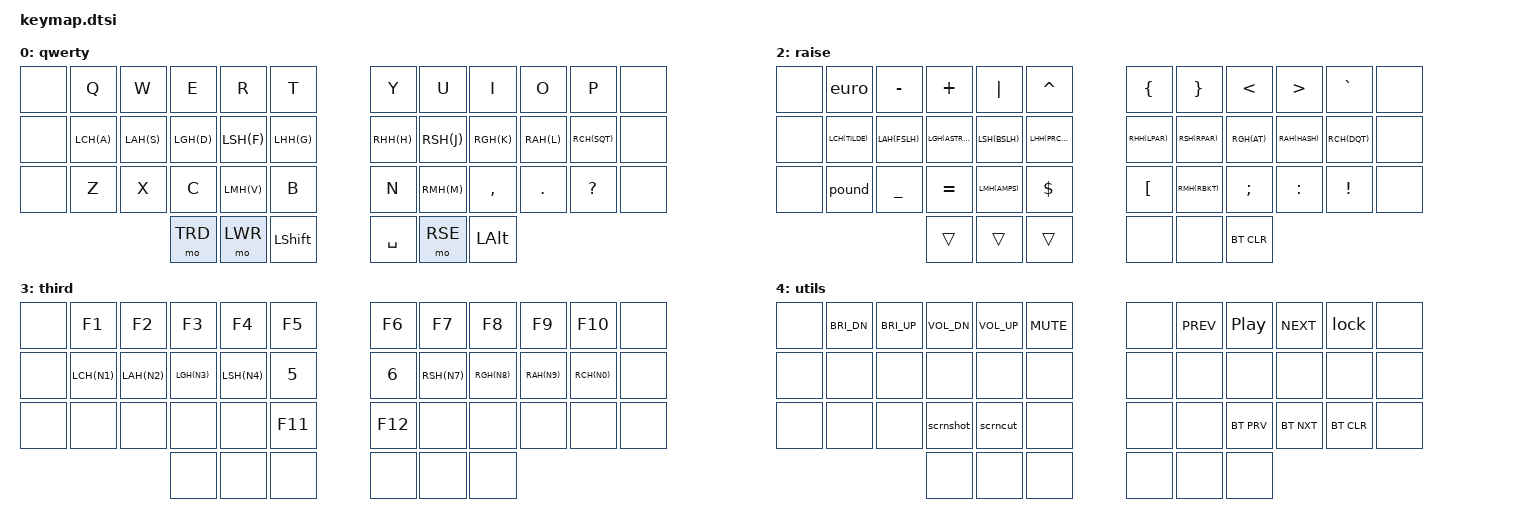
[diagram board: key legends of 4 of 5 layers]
/ {
    keymap {
        compatible = "zmk,keymap";
        qwerty {
            bindings = <
            /*╭───────╭───────────┬───────────┬───────────┬───────────┬───────────╮                           ╭───────────┬───────────┬───────────┬───────────┬───────────╮───────╮*/
            /*│       │     Q     │     W     │     E     │     R     │     T     │                           │     Y     │     U     │     I     │     O     │     P     │       │*/
                &none   &kp Q       &kp W       &kp E       &kp R       &kp T     /*                         */ &kp Y       &kp U       &kp I       &kp O       &kp P       &none
            /*├───────├───────────┼───────────┼───────────┼───────────┼───────────┤                           ├───────────┼───────────┼───────────┼───────────┼───────────┤───────┤*/
            /*│       │     A     │     S     │     D     │     F     │     G     │                           │     H     │     J     │     K     │     L     │     '     │       │*/
                &none   LCH(A)      LAH(S)      LGH(D)      LSH(F)      LHH(G)    /*                         */ RHH(H)      RSH(J)      RGH(K)      RAH(L)      RCH(SQT)    &none
            /*├───────├───────────┼───────────┼───────────┼───────────┼───────────┤                           ├───────────┼───────────┼───────────┼───────────┼───────────┤───────┤*/
            /*│       │     Z     │     X     │     C     │     V     │     B     │                           │     N     │     M     │     ,     │     .     │     ?     │       │*/
                &none   &kp Z       &kp X       &kp C       LMH(V)      &kp B     /*──────────╮   ╭──────────*/ &kp N       RMH(M)      &kp COMMA   &kp DOT     &kp QMARK   &none
            /*╰───────╰───────────┴───────────┴───────────┼───────────┼───────────┤           │   │           ├───────────┼───────────┼───────────┴───────────┴───────────╯───────╯*/
            /*                                            │           │           │   shift   │   │   space   │           │    alt    │                                            */
                                                            &mo TRD     &mo LWR     &kp LSHIFT/* */ &kp SPACE   &mo RSE     &kp LALT
            /*                                            ╰───────────┴───────────┤           │   │           ├───────────┴───────────╯                                            */
            /*                                                                    ╰───────────╯   ╰───────────╯                                                                    */
            >;
        };
        lower {
            bindings = <
            /*╭───────╭───────────┬───────────┬───────────┬───────────┬───────────╮                           ╭───────────┬───────────┬───────────┬───────────┬───────────╮───────╮*/
            /*│       │           │           │           │           │           │                           │           │           │           │           │           │       │*/
                &none   &kp BRI_DN  &kp BRI_UP  &kp VOL_DN  &kp VOL_UP  &kp MUTE  /*                         */ &none       &kp C_PREV  &kp C_PP    &kp C_NEXT  &lock       &none
            /*├───────├───────────┼───────────┼───────────┼───────────┼───────────┤                           ├───────────┼───────────┼───────────┼───────────┼───────────┤───────┤*/
            /*│       │    ctrl   │    alt    │    cmd    │   shift   │ CAPS word │                           │     <     │     v     │     ^     │     >     │           │       │*/
                &none   &kp LCTRL   &kp LALT    &kp LGUI    &kp LSHIFT  &caps_word/*                         */ &kp LEFT    &kp DOWN    &kp UP      &kp RIGHT   &none       &none
            /*├───────├───────────┼───────────┼───────────┼───────────┼───────────┤                           ├───────────┼───────────┼───────────┼───────────┼───────────┤───────┤*/
            /*│       │           │           │ screenshot│ screencut │           │                           │ backspace │   enter   │    tab    │    esc    │   delete  │       │*/
                &none   &none       &none       &scrnshot   &scrncut    RP        /*──────────╮   ╭──────────*/ &kp BSPC    &kp RET     &kp TAB     &kp ESC     &kp DEL     &none
            /*╰───────╰───────────┴───────────┴───────────┼───────────┼───────────┤           │   │           ├───────────┼───────────┼───────────┴───────────┴───────────╯───────╯*/
            /*                                            │           │[activator]│           │   │           │           │           │                                            */
                                                            &bt BT_CLR  &none       &none     /* */ &trans      &trans      &trans 
            /*                                            ╰───────────┴───────────┤           │   │           ├───────────┴───────────╯                                            */
            /*                                                                    ╰───────────╯   ╰───────────╯                                                                    */
            >;
        };
        raise {
            bindings = <
            /*╭───────╭───────────┬───────────┬───────────┬───────────┬───────────╮                           ╭───────────┬───────────┬───────────┬───────────┬───────────╮───────╮*/
            /*│       │     €     │     -     │     +     │     |     │     ^     │                           │     {     │     }     │     <     │     >     │     `     │       │*/
                &none   &euro       &kp MINUS   &kp PLUS    &kp PIPE    &kp CARET /*                         */ &kp LBRC    &kp RBRC    &kp LT      &kp GT      &kp GRAVE   &none
            /*├───────├───────────┼───────────┼───────────┼───────────┼───────────┤                           ├───────────┼───────────┼───────────┼───────────┼───────────┤───────┤*/
            /*│       │     ~     │     /     │     *     │     \     │     %     │                           │     (     │     )     │     @     │     #     │     "     │       │*/
                &none   LCH(TILDE)  LAH(FSLH)   LGH(ASTRK)  LSH(BSLH)   LHH(PRCNT)/*                         */ RHH(LPAR)   RSH(RPAR)   RGH(AT)     RAH(HASH)   RCH(DQT)    &none
            /*├───────├───────────┼───────────┼───────────┼───────────┼───────────┤                           ├───────────┼───────────┼───────────┼───────────┼───────────┤───────┤*/
            /*│       │     £     │     _     │     =     │     &     │     $     │                           │     [     │     ]     │     ;     │     :     │     !     │       │*/
                &none   &pound      &kp UNDER   &kp EQUAL   LMH(AMPS)   &kp DLLR  /*──────────╮   ╭──────────*/ &kp LBKT    RMH(RBKT)   &kp SEMI    &kp COLON   &kp EXCL    &none
            /*╰───────╰───────────┴───────────┴───────────┼───────────┼───────────┤           │   │           ├───────────┼───────────┼───────────┴───────────┴───────────╯───────╯*/
            /*                                            │           │           │           │   │           │[activator]│           │                                            */
                                                            &trans      &trans      &trans    /* */ &none       &none       &bt BT_CLR
            /*                                            ╰───────────┴───────────┤           │   │           ├───────────┴───────────╯                                            */
            /*                                                                    ╰───────────╯   ╰───────────╯                                                                    */
            >;
        };
        third {
            bindings = <
            /*╭───────╭───────────┬───────────┬───────────┬───────────┬───────────╮                           ╭───────────┬───────────┬───────────┬───────────┬───────────╮───────╮*/
            /*│       │    F1     │    F2     │    F3     │    F4     │    F5     │                           │    F6     │    F7     │    F8     │    F9     │    F10    │       │*/
                &none   &kp F1      &kp F2      &kp F3      &kp F4      &kp F5    /*                         */ &kp F6      &kp F7      &kp F8      &kp F9      &kp F10     &none
            /*├───────├───────────┼───────────┼───────────┼───────────┼───────────┤                           ├───────────┼───────────┼───────────┼───────────┼───────────┤───────┤*/
            /*│       │     1     │     2     │     3     │     4     │     5     │                           │     6     │     7     │     8     │     9     │     10    │       │*/
                &none   LCH(N1)     LAH(N2)     LGH(N3)     LSH(N4)     &kp N5    /*                         */ &kp N6      RSH(N7)     RGH(N8)     RAH(N9)     RCH(N0)     &none
            /*├───────├───────────┼───────────┼───────────┼───────────┼───────────┤                           ├───────────┼───────────┼───────────┼───────────┼───────────┤───────┤*/
            /*│       │           │           │           │           │    F11    │                           │    F12    │           │           │           │           │       │*/
                &none   &none       &none       &none       &none       &kp F11   /*──────────╮   ╭──────────*/ &kp F12     &none       &none       &none       &none       &none
            /*╰───────╰───────────┴───────────┴───────────┼───────────┼───────────┤           │   │           ├───────────┼───────────┼───────────┴───────────┴───────────╯───────╯*/
            /*                                            │[activator]│           │           │   │           │           │           │                                            */
                                                            &none       &none       &none     /* */ &none       &none       &none
            /*                                            ╰───────────┴───────────┤           │   │           ├───────────┴───────────╯                                            */
            /*                                                                    ╰───────────╯   ╰───────────╯                                                                    */
            >;
        };
        utils {
            bindings = <
            /*╭───────╭───────────┬───────────┬───────────┬───────────┬───────────╮                           ╭───────────┬───────────┬───────────┬───────────┬───────────╮───────╮*/
            /*│       │           │           │           │           │           │                           │           │           │           │           │           │       │*/
                &none   &kp BRI_DN  &kp BRI_UP  &kp VOL_DN  &kp VOL_UP  &kp MUTE  /*                         */ &none       &kp C_PREV  &kp C_PP    &kp C_NEXT  &lock       &none
            /*├───────├───────────┼───────────┼───────────┼───────────┼───────────┤                           ├───────────┼───────────┼───────────┼───────────┼───────────┤───────┤*/
            /*│       │           │           │           │           │           │                           │           │           │           │           │           │       │*/
                &none   &none       &none       &none       &none       &none     /*                         */ &none       &none       &none       &none       &none       &none
            /*├───────├───────────┼───────────┼───────────┼───────────┼───────────┤                           ├───────────┼───────────┼───────────┼───────────┼───────────┤───────┤*/
            /*│       │           │           │ screenshot│ screencut │           │                           │           │           │           │           │           │       │*/
                &none   &none       &none       &scrnshot   &scrncut    &none     /*──────────╮   ╭──────────*/ &none       &none       &bt BT_PRV  &bt BT_NXT  &bt BT_CLR  &none
            /*╰───────╰───────────┴───────────┴───────────┼───────────┼───────────┤           │   │           ├───────────┼───────────┼───────────┴───────────┴───────────╯───────╯*/
            /*                                            │           │[activator]│           │   │           │[activator]│           │                                            */
                                                            &none       &none       &none     /* */ &none       &none       &none
            /*                                            ╰───────────┴───────────┤           │   │           ├───────────┴───────────╯                                            */
            /*                                                                    ╰───────────╯   ╰───────────╯                                                                    */
            >;
        };
            /*╭───────╭───────────┬───────────┬───────────┬───────────┬───────────╮                           ╭───────────┬───────────┬───────────┬───────────┬───────────╮───────╮*/
            /*│       │           │           │           │           │           │                           │           │           │           │           │           │       │*/
            /*├───────├───────────┼───────────┼───────────┼───────────┼───────────┤                           ├───────────┼───────────┼───────────┼───────────┼───────────┤───────┤*/
            /*│       │           │           │           │           │           │                           │           │           │           │           │           │       │*/
            /*├───────├───────────┼───────────┼───────────┼───────────┼───────────┤                           ├───────────┼───────────┼───────────┼───────────┼───────────┤───────┤*/
            /*│       │           │           │           │           │           ├───────────╮   ╭───────────┤           │           │           │           │           │       │*/
            /*╰───────┴───────────┴───────────┴───────────┼───────────┼───────────┤           │   │           ├───────────┼───────────┼───────────┴───────────┴───────────╯───────╯*/
            /*                                            │           │           │           │   │           │           │           │                                            */
            /*                                            ╰───────────┴───────────┤           │   │           ├───────────┴───────────╯                                            */
            /*                                                                    ╰───────────╯   ╰───────────╯                                                                    */
    };
};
